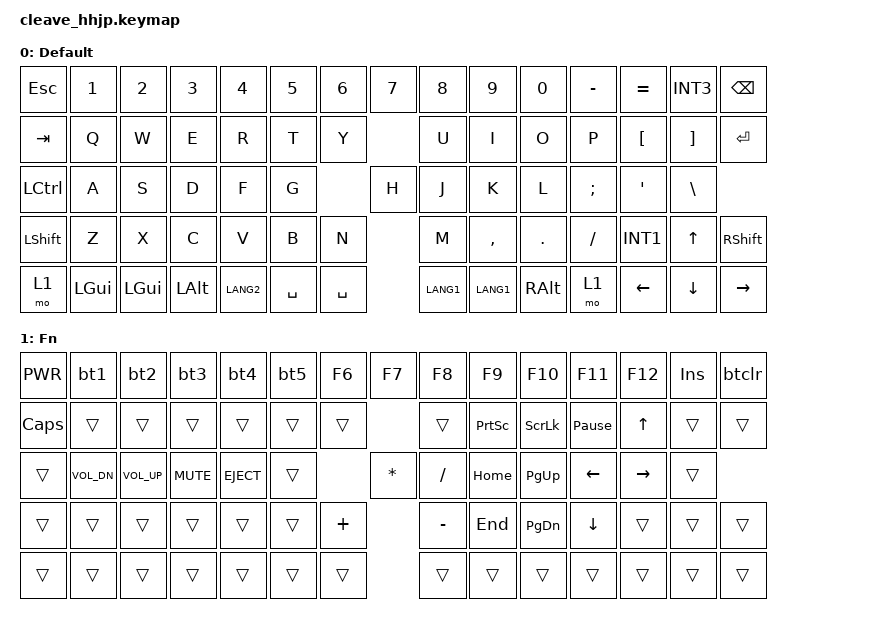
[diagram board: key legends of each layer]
/*
 * Copyright (c) 2025
 * SPDX-License-Identifier: MIT
 */

#include <behaviors.dtsi>
#include <dt-bindings/zmk/keys.h>
#include <dt-bindings/zmk/bt.h>

/ {
	chosen {
		zmk,physical-layout = &physical_layout;
	};

	key_physical_attrs: key_physical_attrs {
		compatible = "zmk,key-physical-attrs";
		#key-cells = <7>;
	};

	physical_layout: physical_layout {
		compatible = "zmk,physical-layout";
		display-name = "HHKB JP Split";

		transform = <&default_transform>;

		keys  // 70 keys: width, height, x, y, r, rx, ry (in centidecimillimeters, 1U = 1905)
			// Row 0: ESC + 6 keys (left) + gap 2U + 8 keys (right)
			= <&key_physical_attrs 1905 1905    0    0 0 0 0>  // ESC
			, <&key_physical_attrs 1905 1905 1905    0 0 0 0>  // 1
			, <&key_physical_attrs 1905 1905 3810    0 0 0 0>  // 2
			, <&key_physical_attrs 1905 1905 5715    0 0 0 0>  // 3
			, <&key_physical_attrs 1905 1905 7620    0 0 0 0>  // 4
			, <&key_physical_attrs 1905 1905 9525    0 0 0 0>  // 5
			, <&key_physical_attrs 1905 1905 11430   0 0 0 0>  // 6
			, <&key_physical_attrs 1905 1905 15240   0 0 0 0>  // 7 (gap 2U = 3810)
			, <&key_physical_attrs 1905 1905 17145   0 0 0 0>  // 8
			, <&key_physical_attrs 1905 1905 19050   0 0 0 0>  // 9
			, <&key_physical_attrs 1905 1905 20955   0 0 0 0>  // 0
			, <&key_physical_attrs 1905 1905 22860   0 0 0 0>  // -
			, <&key_physical_attrs 1905 1905 24765   0 0 0 0>  // ^
			, <&key_physical_attrs 1905 1905 26670   0 0 0 0>  // ¥
			, <&key_physical_attrs 1905 1905 28575   0 0 0 0>  // BS
			// Row 1: Tab(1.5U) + 5 keys (left) + gap 2U + 7 keys + Enter(1.25U×2h) (right)
			, <&key_physical_attrs 2858 1905    0 1905 0 0 0>  // Tab (1.5U = 2857.5, rounded)
			, <&key_physical_attrs 1905 1905 2858 1905 0 0 0>  // Q
			, <&key_physical_attrs 1905 1905 4763 1905 0 0 0>  // W
			, <&key_physical_attrs 1905 1905 6668 1905 0 0 0>  // E
			, <&key_physical_attrs 1905 1905 8573 1905 0 0 0>  // R
			, <&key_physical_attrs 1905 1905 10478 1905 0 0 0> // T
			, <&key_physical_attrs 1905 1905 15240 1905 0 0 0> // Y (gap 2U)
			, <&key_physical_attrs 1905 1905 17145 1905 0 0 0> // U
			, <&key_physical_attrs 1905 1905 19050 1905 0 0 0> // I
			, <&key_physical_attrs 1905 1905 20955 1905 0 0 0> // O
			, <&key_physical_attrs 1905 1905 22860 1905 0 0 0> // P
			, <&key_physical_attrs 1905 1905 24765 1905 0 0 0> // @
			, <&key_physical_attrs 1905 1905 26670 1905 0 0 0> // [
			, <&key_physical_attrs 2381 3810 28575 1905 0 0 0> // Enter (1.25U×2h = 2381.25×3810)
			// Row 2: Ctrl(1.75U) + 5 keys (left) + gap 2U + 7 keys (right)
			, <&key_physical_attrs 3334 1905    0 3810 0 0 0>  // Ctrl (1.75U = 3333.75)
			, <&key_physical_attrs 1905 1905 3334 3810 0 0 0>  // A
			, <&key_physical_attrs 1905 1905 5239 3810 0 0 0>  // S
			, <&key_physical_attrs 1905 1905 7144 3810 0 0 0>  // D
			, <&key_physical_attrs 1905 1905 9049 3810 0 0 0>  // F
			, <&key_physical_attrs 1905 1905 10954 3810 0 0 0> // G
			, <&key_physical_attrs 1905 1905 15240 3810 0 0 0> // H (gap 2U)
			, <&key_physical_attrs 1905 1905 17145 3810 0 0 0> // J
			, <&key_physical_attrs 1905 1905 19050 3810 0 0 0> // K
			, <&key_physical_attrs 1905 1905 20955 3810 0 0 0> // L
			, <&key_physical_attrs 1905 1905 22860 3810 0 0 0> // ;
			, <&key_physical_attrs 1905 1905 24765 3810 0 0 0> // :
			, <&key_physical_attrs 1905 1905 26670 3810 0 0 0> // ]
			// Row 3: LShift(2U) + 5 keys (left) + gap 2U + 6 keys + Up + RShift (right)
			, <&key_physical_attrs 3810 1905    0 5715 0 0 0>  // LShift (2U = 3810)
			, <&key_physical_attrs 1905 1905 3810 5715 0 0 0>  // Z
			, <&key_physical_attrs 1905 1905 5715 5715 0 0 0>  // X
			, <&key_physical_attrs 1905 1905 7620 5715 0 0 0>  // C
			, <&key_physical_attrs 1905 1905 9525 5715 0 0 0>  // V
			, <&key_physical_attrs 1905 1905 11430 5715 0 0 0> // B
			, <&key_physical_attrs 1905 1905 15240 5715 0 0 0> // N (gap 2U)
			, <&key_physical_attrs 1905 1905 17145 5715 0 0 0> // M
			, <&key_physical_attrs 1905 1905 19050 5715 0 0 0> // <
			, <&key_physical_attrs 1905 1905 20955 5715 0 0 0> // >
			, <&key_physical_attrs 1905 1905 22860 5715 0 0 0> // /
			, <&key_physical_attrs 1905 1905 24765 5715 0 0 0> // _
			, <&key_physical_attrs 1905 1905 26670 5715 0 0 0> // Up
			, <&key_physical_attrs 1905 1905 28575 5715 0 0 0> // RShift
			// Row 4: Fn + gap 0.25U + 4 keys + Space(1.25U) (left) + gap 2U + Space(1.25U) + 3 keys + gap 0.25U + 3 arrows (right)
			, <&key_physical_attrs 1905 1905    0 7620 0 0 0>  // Fn
			, <&key_physical_attrs 1905 1905 2381 7620 0 0 0>  // Win (gap 0.25U = 476.25)
			, <&key_physical_attrs 1905 1905 4286 7620 0 0 0>  // Cmd
			, <&key_physical_attrs 1905 1905 6191 7620 0 0 0>  // Alt
			, <&key_physical_attrs 1905 1905 8096 7620 0 0 0>  // E/J
			, <&key_physical_attrs 2381 1905 10001 7620 0 0 0> // Space L (1.25U = 2381.25)
			, <&key_physical_attrs 2381 1905 15240 7620 0 0 0> // Space R (gap 2U, 1.25U)
			, <&key_physical_attrs 1905 1905 17621 7620 0 0 0> // E/J
			, <&key_physical_attrs 1905 1905 19526 7620 0 0 0> // Kana
			, <&key_physical_attrs 1905 1905 21431 7620 0 0 0> // Alt
			, <&key_physical_attrs 1905 1905 23336 7620 0 0 0> // Fn
			, <&key_physical_attrs 1905 1905 25717 7620 0 0 0> // Left (gap 0.25U)
			, <&key_physical_attrs 1905 1905 27622 7620 0 0 0> // Down
			, <&key_physical_attrs 1905 1905 29527 7620 0 0 0> // Right
			;
	};

	behaviors {
		bt1: bluetooth_morph_1 {
			compatible = "zmk,behavior-mod-morph";
			label = "BT_MORPH_1";
			#binding-cells = <0>;
			bindings = <&kp F1>, <&bt BT_SEL 0>;
			mods = <(MOD_LCTL|MOD_RCTL)>;
		};
		bt2: bluetooth_morph_2 {
			compatible = "zmk,behavior-mod-morph";
			label = "BT_MORPH_2";
			#binding-cells = <0>;
			bindings = <&kp F2>, <&bt BT_SEL 1>;
			mods = <(MOD_LCTL|MOD_RCTL)>;
		};
		bt3: bluetooth_morph_3 {
			compatible = "zmk,behavior-mod-morph";
			label = "BT_MORPH_3";
			#binding-cells = <0>;
			bindings = <&kp F3>, <&bt BT_SEL 2>;
			mods = <(MOD_LCTL|MOD_RCTL)>;
		};
		bt4: bluetooth_morph_4 {
			compatible = "zmk,behavior-mod-morph";
			label = "BT_MORPH_4";
			#binding-cells = <0>;
			bindings = <&kp F4>, <&bt BT_SEL 3>;
			mods = <(MOD_LCTL|MOD_RCTL)>;
		};
		bt5: bluetooth_morph_5 {
			compatible = "zmk,behavior-mod-morph";
			label = "BT_MORPH_5";
			#binding-cells = <0>;
			bindings = <&kp F5>, <&bt BT_SEL 4>;
			mods = <(MOD_LCTL|MOD_RCTL)>;
		};
		btclr: bluetooth_clear_morph {
			compatible = "zmk,behavior-mod-morph";
			label = "BT_CLR_MORPH";
			#binding-cells = <0>;
			bindings = <&kp DEL>, <&bt BT_CLR>;
			mods = <(MOD_LCTL|MOD_RCTL)>;
		};
	};

	keymap {
		compatible = "zmk,keymap";

		default_layer {
			label = "Default";
			bindings = <
    &kp ESC  &kp N1   &kp N2   &kp N3   &kp N4   &kp N5   &kp N6                               &kp N7   &kp N8   &kp N9   &kp N0   &kp MINUS &kp EQUAL &kp INT3 &kp BSPC
    &kp TAB  &kp Q    &kp W    &kp E    &kp R    &kp T                                         &kp Y    &kp U    &kp I    &kp O    &kp P    &kp LBKT &kp RBKT &kp RET
    &kp LCTRL &kp A   &kp S    &kp D    &kp F    &kp G                                         &kp H    &kp J    &kp K    &kp L    &kp SEMI &kp SQT  &kp BSLH
    &kp LSHFT &kp Z   &kp X    &kp C    &kp V    &kp B                                         &kp N    &kp M    &kp COMMA &kp DOT &kp FSLH &kp INT1 &kp UP  &kp RSHFT
    &mo 1    &kp LGUI &kp LGUI &kp LALT &kp LANG2 &kp SPACE                                     &kp SPACE &kp LANG1 &kp LANG1 &kp RALT &mo 1   &kp LEFT &kp DOWN &kp RIGHT
			>;
		};

		fn_layer {
			label = "Fn";
			bindings = <
    &kp C_PWR &bt1    &bt2     &bt3     &bt4     &bt5     &kp F6                               &kp F7   &kp F8   &kp F9   &kp F10  &kp F11  &kp F12  &kp INS  &btclr
    &kp CAPS &trans   &trans   &trans   &trans   &trans                                        &trans   &trans   &kp PSCRN &kp SLCK &kp PAUSE_BREAK &kp UP &trans &trans
    &trans   &kp C_VOL_DN &kp C_VOL_UP &kp C_MUTE &kp C_EJECT &trans                          &kp STAR &kp FSLH &kp HOME &kp PG_UP &kp LEFT &kp RIGHT &trans
    &trans   &trans   &trans   &trans   &trans   &trans                                        &kp PLUS &kp MINUS &kp END &kp PG_DN &kp DOWN &trans   &trans   &trans
    &trans   &trans   &trans   &trans   &trans   &trans                                        &trans   &trans   &trans   &trans   &trans   &trans   &trans   &trans
			>;
		};
	};
};
